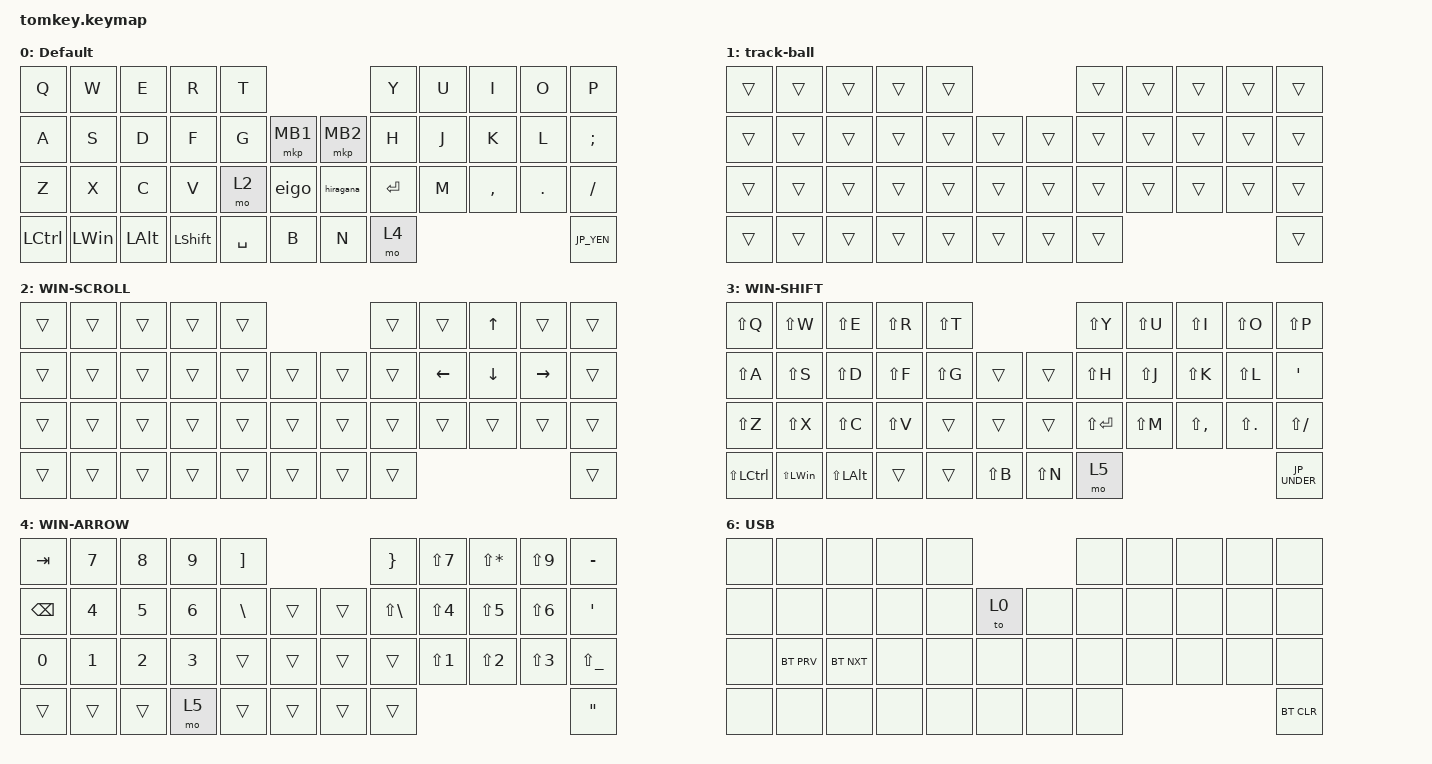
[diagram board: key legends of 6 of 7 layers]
#include <behaviors.dtsi>
#include <dt-bindings/zmk/bt.h>
#include <dt-bindings/zmk/keys.h>
#include <dt-bindings/zmk/pointing.h>

#define JP_ZKHK  GRAVE        // Zenkaku ↔ Hankaku ↔ Kanji (半角 ↔ 全角 ↔ 漢字)
#define JP_MINUS MINUS        // -
#define JP_CARET EQUAL        // ^
#define JP_YEN   INT3         // ¥
#define JP_AT    LBKT         // @
#define JP_LBKT  RBKT         // [
#define JP_EISU  CAPS         // Eisū (英数)
#define JP_SEMI  SEMI         // ;
#define JP_COLON SQT          // :
#define JP_RBKT  NUHS         // ]
#define JP_COMMA COMMA        // ,
#define JP_DOT   DOT          // .
#define JP_SLASH SLASH        // /
#define JP_BSLH  INT1         // (backslash)
#define JP_MHEN  INT5         // Muhenkan (無変換)
#define JP_HENK  INT4         // Henkan (変換)
#define JP_KANA  INT2         // Katakana ↔ Hiragana ↔ Rōmaji (カタカナ ↔ ひらがな ↔ ローマ字)
#define JP_EXCL  LS(N1)       // !
#define JP_DQT   LS(N2)       // "
#define JP_HASH  LS(N3)       // #
#define JP_DLLR  LS(N4)       // $
#define JP_PRCNT LS(N5)       // %
#define JP_AMPS  LS(N6)       // &
#define JP_SQT   LS(N7)       // '
#define JP_LPAR  LS(N8)       // (
#define JP_RPAR  LS(N9)       // )
#define JP_EQUAL LS(JP_MINUS) // =
#define JP_TILDE LS(JP_CARET) // ~
#define JP_PIPE  LS(JP_YEN)   // |
#define JP_GRAVE LS(JP_AT)    // `
#define JP_LBRC  LS(JP_LBKT)  // {
#define JP_CAPS  LS(JP_EISU)  // Caps Lock
#define JP_PLUS  LS(JP_SEMI)  // +
#define JP_ASTRK LS(JP_COLON) // *
#define JP_RBRC  LS(JP_RBKT)  // }
#define JP_LT    LS(JP_COMMA) // <
#define JP_RT    LS(JP_DOT)   // >
#define JP_QMARK LS(JP_SLASH) // ?
#define JP_UNDER LS(JP_BSLH)  // _

/ {
    macros {
        hiragana: hiragana {
            compatible = "zmk,behavior-macro";
            #binding-cells = <0>;
            bindings = <&kp INT_HENKAN &kp LANG1>;
            label = "HIRAGANA";
        };

        eigo: eigo {
            compatible = "zmk,behavior-macro";
            #binding-cells = <0>;
            bindings = <&kp INT_MUHENKAN &kp LANG2>;
            label = "EIGO";
        };
    };

    keymap {
        compatible = "zmk,keymap";

        WIN-DEFAULT {
            bindings = <
&kp Q             &kp W         &kp E         &kp R           &kp T                               &kp Y       &kp U  &kp I      &kp O    &kp P
&kp A             &kp S         &kp D         &kp F           &kp G      &mkp MB1      &mkp MB2   &kp H       &kp J  &kp K      &kp L    &kp SEMICOLON
&kp Z             &kp X         &kp C         &kp V           &mo 2      &eigo         &hiragana  &kp RETURN  &kp M  &kp COMMA  &kp DOT  &kp SLASH
&kp LEFT_CONTROL  &kp LEFT_WIN  &kp LEFT_ALT  &kp LEFT_SHIFT  &kp SPACE  &kp B         &kp N      &mo 4                                  &kp JP_YEN
            >;

            label = "Default";
        };

        track-ball {
            bindings = <
&trans  &trans  &trans  &trans  &trans                      &trans  &trans  &trans  &trans  &trans
&trans  &trans  &trans  &trans  &trans  &trans      &trans  &trans  &trans  &trans  &trans  &trans
&trans  &trans  &trans  &trans  &trans  &trans      &trans  &trans  &trans  &trans  &trans  &trans
&trans  &trans  &trans  &trans  &trans  &trans      &trans  &trans                          &trans
            >;
        };

        WIN-SCROLL {
            bindings = <
&trans  &trans  &trans  &trans  &trans                      &trans  &trans          &kp UP_ARROW    &trans           &trans
&trans  &trans  &trans  &trans  &trans  &trans      &trans  &trans  &kp LEFT_ARROW  &kp DOWN_ARROW  &kp RIGHT_ARROW  &trans
&trans  &trans  &trans  &trans  &trans  &trans      &trans  &trans  &trans          &trans          &trans           &trans
&trans  &trans  &trans  &trans  &trans  &trans      &trans  &trans                                                   &trans
            >;
        };

        WIN-SHIFT {
            bindings = <
&kp LS(Q)      &kp LS(W)         &kp LS(E)         &kp LS(R)  &kp LS(T)                            &kp LS(Y)    &kp LS(U)  &kp LS(I)      &kp LS(O)       &kp LS(P)
&kp LS(A)      &kp LS(S)         &kp LS(D)         &kp LS(F)  &kp LS(G)  &trans         &trans     &kp LS(H)    &kp LS(J)  &kp LS(K)      &kp LS(L)       &kp SINGLE_QUOTE
&kp LS(Z)      &kp LS(X)         &kp LS(C)         &kp LS(V)  &trans     &trans         &trans     &kp LS(RET)  &kp LS(M)  &kp LS(COMMA)  &kp LS(PERIOD)  &kp LS(SLASH)
&kp LS(LCTRL)  &kp LS(LEFT_WIN)  &kp LS(LEFT_ALT)  &trans     &trans     &kp LS(B)      &kp LS(N)  &mo 5                                                  &kp JP_UNDER
            >;
        };

        WIN-ARROW {
            bindings = <
&kp TAB        &kp N7  &kp N8  &kp N9  &kp RIGHT_BRACKET                      &kp RIGHT_BRACE    &kp LS(N7)        &kp LS(ASTERISK)  &kp LS(N9)        &kp MINUS
&kp BACKSPACE  &kp N4  &kp N5  &kp N6  &kp BACKSLASH      &trans      &trans  &kp LS(BACKSLASH)  &kp LS(NUMBER_4)  &kp LS(NUMBER_5)  &kp LS(NUMBER_6)  &kp SINGLE_QUOTE
&kp N0         &kp N1  &kp N2  &kp N3  &trans             &trans      &trans  &trans             &kp LS(NUMBER_1)  &kp LS(NUMBER_2)  &kp LS(NUMBER_3)  &kp LS(UNDERSCORE)
&trans         &trans  &trans  &mo 5   &trans             &trans      &trans  &trans                                                                   &kp DOUBLE_QUOTES
            >;
        };

        WIN-FUNCTION {
            bindings = <
&kp TAB        &kp F7  &kp F8  &kp F9   &kp RIGHT_BRACKET                                  &kp RIGHT_BRACE    &trans        &trans        &kp JP_AT                    &kp MINUS
&kp BACKSPACE  &kp F4  &kp F5  &kp F6   &kp BACKSLASH      &kp F11      &trans             &kp LS(BACKSLASH)  &kp JP_TILDE  &kp JP_CARET  &kp RS(LA(INTERNATIONAL_3))  &trans
&kp F1         &kp F2  &kp F3  &trans   &kp F12            &trans       &kp RIGHT_CONTROL  &trans             &trans        &trans        &kp LS(UNDERSCORE)           &to 6
&trans         &trans  &trans  &kp F10  &trans             &trans       &trans             &kp DOUBLE_QUOTES
            >;
        };

        USB {
            bindings = <
&none  &none       &none       &none  &none                    &none  &none  &none  &none  &none
&none  &none       &none       &none  &none  &to 0      &none  &none  &none  &none  &none  &none
&none  &bt BT_PRV  &bt BT_NXT  &none  &none  &none      &none  &none  &none  &none  &none  &none
&none  &none       &none       &none  &none  &none      &none  &none                       &bt BT_CLR
            >;
        };
    };
};
